# IMM100A register map
Vendor: Infineon; File version: 0.8.0 (Reference Manual v0.8.0)
CPU: CM0 r0p0, little endian, no MPU, no FPU, 2 interrupt priority bits
Registers are 32-bit, read-write, reset 0x0 unless marked. A register's access mark holds for its fields unless they carry their own. Offsets are from the block's base; [hi:lo] are bit positions; 'fields as' and 'values as' point back to an identical list.

## MCE — Motion Control Engine
Base 0x40030000
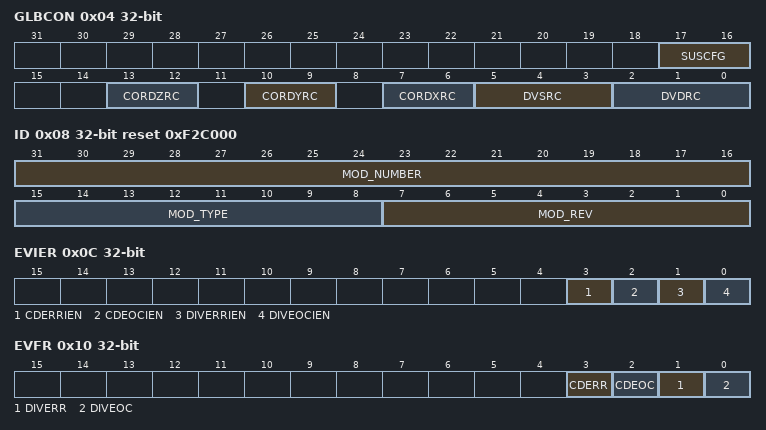
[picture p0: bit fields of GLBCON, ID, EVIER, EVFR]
0x04 GLBCON — Global Control Register
  [17:16] SUSCFG — Suspend Mode Configuration
    0=Suspend mode is never entered; 1=Hard suspend mode will be entered when CPU is halted; 2=Soft suspend mode will be entered when CPU is halted
  [13:12] CORDZRC — CORDZ Register Result Chaining
    0=No result chaining is selected; 1=QUOT register is the selected source; 2=RMD register is the selected source
  [10:9] CORDYRC — CORDY Register Result Chaining
    values as CORDZRC
  [7:6] CORDXRC — CORDX Register Result Chaining
    values as CORDZRC
  [5:3] DVSRC — Divisor Register Result Chaining
    0=No result chaining is selected; 1=QUOT register is the selected source; 2=RMD register is the selected source; 3=CORRX is the selected source; 4=CORRY is the selected source; 5=CORRZ is the selected source
  [2:0] DVDRC — Dividend Register Result Chaining
    values as DVSRC
0x08 ID ro reset 0xF2C000 (reset mask 0xFFFFFF00) — Module Identification Register
  [31:16] MOD_NUMBER — Module Number Value
  [15:8] MOD_TYPE — Module Type
  [7:0] MOD_REV — Module Revision Number
0x0C EVIER — Event Interrupt Enable Register
  [3] CDERRIEN — CORDIC Error Interrupt Enable
    0=CORDIC error interrupt generation is disabled; 1=CORDIC error interrupt generation is enabled
  [2] CDEOCIEN — CORDIC End of Calculation Interrupt Enable
    0=CORDIC end of calculation interrupt generation is disabled; 1=CORDIC end of calculation interrupt generation is enabled
  [1] DIVERRIEN — Divider Error Interrupt Enable
    0=Divider error interrupt generation is disabled; 1=Divider error interrupt generation is enabled
  [0] DIVEOCIEN — Divider End of Calculation Interrupt Enable
    0=Divider end of calculation interrupt generation is disabled; 1=Divider end of calculation interrupt generation is enabled
0x10 EVFR ro — Event Flag Register
  [3] CDERR — CORDIC Error Event Flag
    0=CORDIC error event has not been detected; 1=CORDIC error event has been detected
  [2] CDEOC — CORDIC End of Calculation Event Flag
    0=CORDIC end of calculation event has not been detected; 1=CORDIC end of calculation event has been detected
  [1] DIVERR — Divider Error Event Flag
    0=Divider error event has not been detected; 1=Divider error event has been detected
  [0] DIVEOC — Divider End of Calculation Event Flag
    0=Divider end of calculation event has not been detected; 1=Divider end of calculation event has been detected
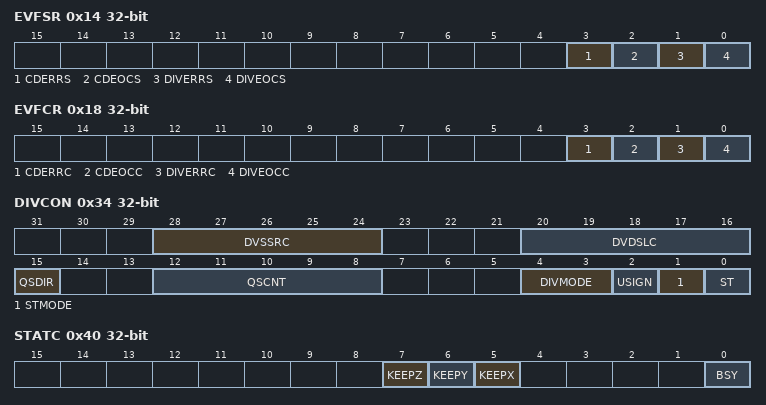
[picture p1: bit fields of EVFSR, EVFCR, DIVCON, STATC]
0x14 EVFSR wo — Event Flag Set Register
  [3] CDERRS — CORDIC Error Event Flag Set
    0=No effect; 1=Sets the CORDIC error event flag in EVFR register. Interrupt will be generated if enabled in EVIER register.
  [2] CDEOCS — CORDIC Event Flag Set
    0=No effect; 1=Sets the CORDIC end of calculation event flag in EVFR register. Interrupt will be generated if enabled in EVIER register.
  [1] DIVERRS — Divider Error Event Flag Set
    0=No effect; 1=Sets the Divider error event flag in EVFR register. Interrupt will be generated if enabled in EVIER register.
  [0] DIVEOCS — Divider End of Calculation Event Flag Set
    0=No effect; 1=Sets the Divider end of calculation event flag in EVFR register. Interrupt will be generated if enabled in EVIER register.
0x18 EVFCR wo — Event Flag Clear Register
  [3] CDERRC — CORDIC Error Event Flag Clear
    0=No effect; 1=Clears the CORDIC error event flag in EVFR register
  [2] CDEOCC — CORDIC End of Calculation Event Flag Clear
    0=No effect; 1=Clears the CORDIC end of calculation event flag in EVFR register
  [1] DIVERRC — Divider Error Event Flag Clear
    0=No effect; 1=Clears the Divider error event flag in EVFR register
  [0] DIVEOCC — Divider End of Calculation Event Flag Clear
    0=No effect; 1=Clears the Divider end of calculation event flag in EVFR register
0x20 DVD — Dividend Register
  [31:0] VAL — Dividend Value
0x24 DVS — Divisor Register
  [31:0] VAL — Divisor Value
0x28 QUOT ro — Quotient Register
  [31:0] VAL — Quotient Value
0x2C RMD ro — Remainder Register
  [31:0] VAL — Remainder Value
0x30 DIVST ro — Divider Status Register
  [0] BSY — Busy Indication
    0=Divider is not running any division operation; 1=Divider is still running a division operation
0x34 DIVCON — Divider Control Register
  [28:24] DVSSRC — Divisor Shift Right Count
  [20:16] DVDSLC — Dividend Shift Left Count
  [15] QSDIR — Quotient Shift Direction
    0=Left shift; 1=Right shift
  [12:8] QSCNT — Quotient Shift Count
  [4:3] DIVMODE — Division Mode
    0=32-bit divide by 32-bit; 1=32-bit divide by 16-bit; 2=16-bit divide by 16-bit
  [2] USIGN — Unsigned Division Enable
    0=Signed division is selected; 1=Unsigned division is selected
  [1] STMODE — Start Mode
    0=Calculation is automatically started with a write to DVS register; 1=Calculation is started by setting the ST bit to 1
  [0] ST — Start Bit
    0=No effect; 1=Start the division operation when STMODE=1#
0x40 STATC access per field — CORDIC Status and Data Control Register
  [7] KEEPZ rw — Last Z Result as Initial Data for New Calculation
  [6] KEEPY rw — Last Y Result as Initial Data for New Calculation
  [5] KEEPX rw — Last X Result as Initial Data for New Calculation
  [0] BSY ro — Busy Indication
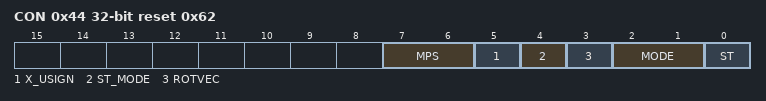
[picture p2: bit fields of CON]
0x44 CON reset 0x62 — CORDIC Control Register
  [7:6] MPS — X and Y Magnitude Prescaler
    0=Divide by 1; 1=Divide by 2 (default); 2=Divide by 4; 3=Reserved, retain the last MPS setting
  [5] X_USIGN — Result Data Format for X in Circular Vectoring Mode
    0=Signed, twos complement; 1=Unsigned (default)
  [4] ST_MODE — Start Method
    0=Auto start of calculation after write access to X parameter data register CORDX(default); 1=Start calculation only after bit ST is set
  [3] ROTVEC — Rotation Vectoring Selection
    0=Vectoring Mode (default); 1=Rotation Mode
  [2:1] MODE — Operating Mode
    0=Linear Mode; 1=Circular Mode (default); 3=Hyperbolic Mode
  [0] ST — Start Calculation
0x48 CORDX — CORDIC X Data Register
  [31:8] DATA — Initial X Parameter Data
0x4C CORDY — CORDIC Y Data Register
  [31:8] DATA — Initial Y Parameter Data
0x50 CORDZ — CORDIC Z Data Register
  [31:8] DATA — Initial Z Parameter Data
0x54 CORRX ro — CORDIC X Result Register
  [31:8] RESULT — X Calculation Result
0x58 CORRY ro — CORDIC Y Result Register
  [31:8] RESULT — Y Calculation Result
0x5C CORRZ ro — CORDIC Z Result Register
  [31:8] RESULT — Z Calculation Result
